VERSION "2.8"

NS_ :

BS_:

BU_: Advantics_Charge_Controller Generic_Power_Modules

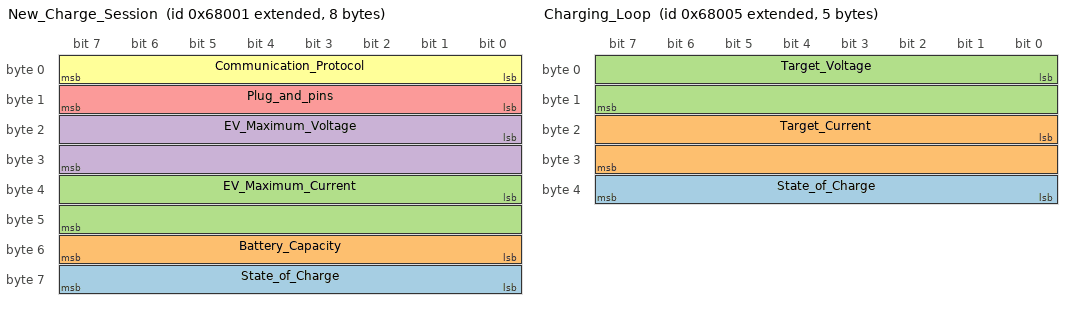
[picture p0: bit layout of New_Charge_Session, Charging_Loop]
BO_ 2147909633 New_Charge_Session: 8 Advantics_Charge_Controller
 SG_ State_of_Charge : 56|8@1+ (1,0) [0|100] "%" Vector__XXX
 SG_ Battery_Capacity : 48|8@1+ (2,0) [0|510] "kWh" Vector__XXX
 SG_ EV_Maximum_Current : 32|16@1+ (0.1,0) [0|0] "Amps" Vector__XXX
 SG_ EV_Maximum_Voltage : 16|16@1+ (0.1,0) [0|0] "Volts" Vector__XXX
 SG_ Plug_and_pins : 8|8@1+ (1,0) [0|0] "" Vector__XXX
 SG_ Communication_Protocol : 0|8@1+ (1,0) [0|0] "" Vector__XXX

BO_ 2147909634 Insulation_Test: 2 Advantics_Charge_Controller
 SG_ Test_Voltage : 0|16@1+ (0.1,0) [0|0] "Volts" Vector__XXX

BO_ 2147909635 Precharge: 4 Advantics_Charge_Controller
 SG_ Maximum_Current : 16|16@1+ (0.1,0) [0|0] "Amps" Vector__XXX
 SG_ Target_Voltage : 0|16@1+ (0.1,0) [0|0] "Volts" Vector__XXX

BO_ 2147909636 Charge_Status_Change: 1 Advantics_Charge_Controller
 SG_ Vehicle_Ready_for_Charging : 0|8@1+ (1,0) [0|0] "" Vector__XXX

BO_ 2147909637 Charging_Loop: 5 Advantics_Charge_Controller
 SG_ State_of_Charge : 32|8@1+ (1,0) [0|100] "%" Vector__XXX
 SG_ Target_Current : 16|16@1- (0.1,0) [0|0] "Amps" Vector__XXX
 SG_ Target_Voltage : 0|16@1+ (0.1,0) [0|0] "Volts" Vector__XXX

BO_ 2147909638 Emergency_Stop: 1 Advantics_Charge_Controller
 SG_ Origin : 0|8@1+ (1,0) [0|0] "" Vector__XXX

BO_ 2147909639 Charge_Session_Finished: 1 Advantics_Charge_Controller
 SG_ State : 0|8@1+ (1,0) [0|0] "" Vector__XXX

BO_ 2147909641 Advantics_Controller_Status: 1 Advantics_Charge_Controller
 SG_ State : 0|8@1+ (1,0) [0|0] "" Vector__XXX

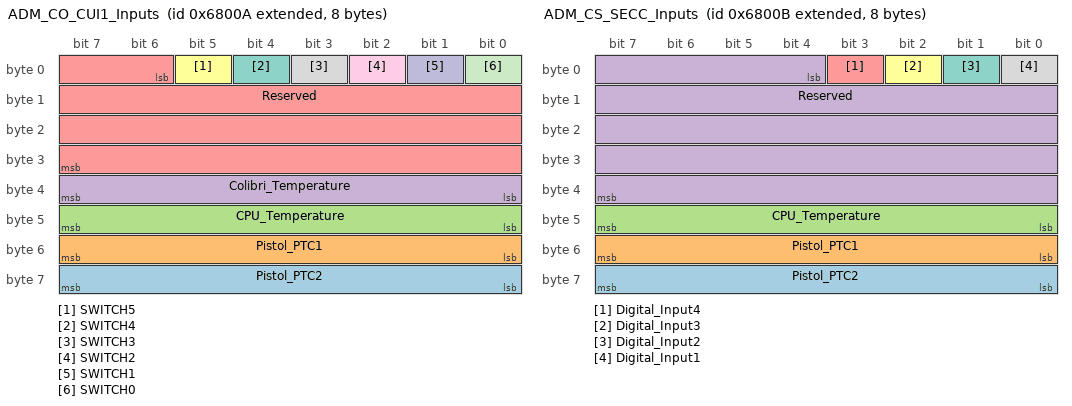
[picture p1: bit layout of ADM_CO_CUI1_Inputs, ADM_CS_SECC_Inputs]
BO_ 2147909642 ADM_CO_CUI1_Inputs: 8 Advantics_Charge_Controller
 SG_ Pistol_PTC2 : 56|8@1+ (1,-40) [-40|215] "°C" Vector__XXX
 SG_ Pistol_PTC1 : 48|8@1+ (1,-40) [-40|215] "°C" Vector__XXX
 SG_ CPU_Temperature : 40|8@1+ (1,-40) [-40|215] "°C" Vector__XXX
 SG_ Colibri_Temperature : 32|8@1+ (1,-40) [-40|215] "°C" Vector__XXX
 SG_ Reserved : 6|26@1+ (1,0) [0|0] "" Vector__XXX
 SG_ SWITCH5 : 5|1@1+ (1,0) [0|1] "" Vector__XXX
 SG_ SWITCH4 : 4|1@1+ (1,0) [0|1] "" Vector__XXX
 SG_ SWITCH3 : 3|1@1+ (1,0) [0|1] "" Vector__XXX
 SG_ SWITCH2 : 2|1@1+ (1,0) [0|1] "" Vector__XXX
 SG_ SWITCH1 : 1|1@1+ (1,0) [0|1] "" Vector__XXX
 SG_ SWITCH0 : 0|1@1+ (1,0) [0|1] "" Vector__XXX

BO_ 2147909643 ADM_CS_SECC_Inputs: 8 Advantics_Charge_Controller
 SG_ Pistol_PTC2 : 56|8@1+ (1,-40) [-40|215] "°C" Vector__XXX
 SG_ Pistol_PTC1 : 48|8@1+ (1,-40) [-40|215] "°C" Vector__XXX
 SG_ CPU_Temperature : 40|8@1+ (1,-40) [-40|215] "°C" Vector__XXX
 SG_ Reserved : 4|36@1+ (1,0) [0|0] "" Vector__XXX
 SG_ Digital_Input4 : 3|1@1+ (1,0) [0|1] "" Vector__XXX
 SG_ Digital_Input3 : 2|1@1+ (1,0) [0|1] "" Vector__XXX
 SG_ Digital_Input2 : 1|1@1+ (1,0) [0|1] "" Vector__XXX
 SG_ Digital_Input1 : 0|1@1+ (1,0) [0|1] "" Vector__XXX

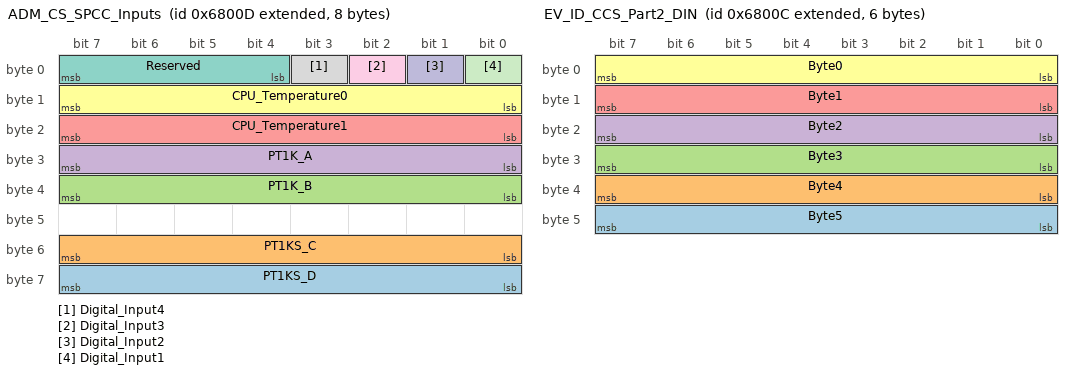
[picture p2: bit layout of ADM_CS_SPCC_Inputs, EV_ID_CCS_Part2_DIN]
BO_ 2147909645 ADM_CS_SPCC_Inputs: 8 Advantics_Charge_Controller
 SG_ PT1KS_D : 56|8@1+ (1,-40) [-40|215] "°C" Vector__XXX
 SG_ PT1KS_C : 48|8@1+ (1,-40) [-40|215] "°C" Vector__XXX
 SG_ PT1K_B : 32|8@1+ (1,-40) [-40|215] "°C" Vector__XXX
 SG_ PT1K_A : 24|8@1+ (1,-40) [-40|215] "°C" Vector__XXX
 SG_ CPU_Temperature1 : 16|8@1+ (1,-40) [-40|215] "°C" Vector__XXX
 SG_ CPU_Temperature0 : 8|8@1+ (1,-40) [-40|215] "°C" Vector__XXX
 SG_ Reserved : 4|4@1+ (1,0) [0|0] "" Vector__XXX
 SG_ Digital_Input4 : 3|1@1+ (1,0) [0|1] "" Vector__XXX
 SG_ Digital_Input3 : 2|1@1+ (1,0) [0|1] "" Vector__XXX
 SG_ Digital_Input2 : 1|1@1+ (1,0) [0|1] "" Vector__XXX
 SG_ Digital_Input1 : 0|1@1+ (1,0) [0|1] "" Vector__XXX

BO_ 2147909644 EV_ID_CCS_Part2_DIN: 6 Advantics_Charge_Controller
 SG_ Byte5 : 40|8@1+ (1,0) [0|0] "" Vector__XXX
 SG_ Byte4 : 32|8@1+ (1,0) [0|0] "" Vector__XXX
 SG_ Byte3 : 24|8@1+ (1,0) [0|0] "" Vector__XXX
 SG_ Byte2 : 16|8@1+ (1,0) [0|0] "" Vector__XXX
 SG_ Byte1 : 8|8@1+ (1,0) [0|0] "" Vector__XXX
 SG_ Byte0 : 0|8@1+ (1,0) [0|0] "" Vector__XXX

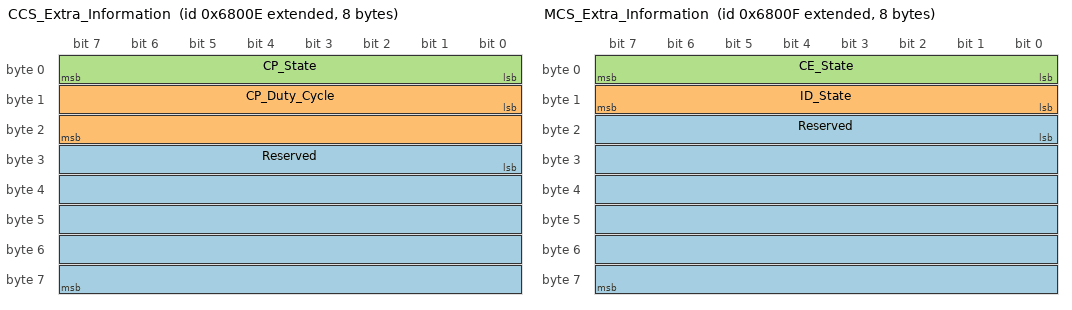
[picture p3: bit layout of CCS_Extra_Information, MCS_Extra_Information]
BO_ 2147909646 CCS_Extra_Information: 8 Advantics_Charge_Controller
 SG_ Reserved : 24|40@1+ (1,0) [0|0] "" Vector__XXX
 SG_ CP_Duty_Cycle : 8|16@1+ (0.1,0) [0|100] "%" Vector__XXX
 SG_ CP_State : 0|8@1+ (1,0) [0|0] "" Vector__XXX

BO_ 2147909647 MCS_Extra_Information: 8 Advantics_Charge_Controller
 SG_ Reserved : 16|48@1+ (1,0) [0|0] "" Vector__XXX
 SG_ ID_State : 8|8@1+ (1,0) [0|0] "" Vector__XXX
 SG_ CE_State : 0|8@1+ (1,0) [0|0] "" Vector__XXX

BO_ 2147909648 Charger_Diagnostic_Status: 8 Advantics_Charge_Controller
 SG_ Reserved_Flags : 35|29@1+ (1,0) [0|0] "" Vector__XXX
 SG_ PowerPermitWithdrawn : 34|1@1+ (1,0) [0|0] "" Vector__XXX
 SG_ SessionStoppedBeforeCharge : 33|1@1+ (1,0) [0|0] "" Vector__XXX
 SG_ EVChargingSystemIncompatibility : 32|1@1+ (1,0) [0|0] "" Vector__XXX
 SG_ EVChargingVoltageOutOfRange : 31|1@1+ (1,0) [0|0] "" Vector__XXX
 SG_ EVChargingCurrentDifferential : 30|1@1+ (1,0) [0|0] "" Vector__XXX
 SG_ EVRESSMalfunction : 29|1@1+ (1,0) [0|0] "" Vector__XXX
 SG_ EVConnectorLockFault : 28|1@1+ (1,0) [0|0] "" Vector__XXX
 SG_ EVShiftPosition : 27|1@1+ (1,0) [0|0] "" Vector__XXX
 SG_ EVRESSTemperatureInhibit : 26|1@1+ (1,0) [0|0] "" Vector__XXX
 SG_ CommunicationSetupTimeout : 25|1@1+ (1,0) [0|0] "" Vector__XXX
 SG_ V2GProtocolNotAllowed : 24|1@1+ (1,0) [0|0] "" Vector__XXX
 SG_ V2GParameterNotSupported : 23|1@1+ (1,0) [0|0] "" Vector__XXX
 SG_ V2GSessionIDUnexpected : 22|1@1+ (1,0) [0|0] "" Vector__XXX
 SG_ V2GSequenceError : 21|1@1+ (1,0) [0|0] "" Vector__XXX
 SG_ ChargeEnableStateUnexpected : 20|1@1+ (1,0) [0|0] "" Vector__XXX
 SG_ ChargeEnableFault : 19|1@1+ (1,0) [0|0] "" Vector__XXX
 SG_ ControlPilotStateUnexpected : 18|1@1+ (1,0) [0|0] "" Vector__XXX
 SG_ ControlPilotFault : 17|1@1+ (1,0) [0|0] "" Vector__XXX
 SG_ BidirectionalNotSupported : 16|1@1+ (1,0) [0|0] "" Vector__XXX
 SG_ RangeModeNotSupported : 15|1@1+ (1,0) [0|0] "" Vector__XXX
 SG_ CANBusError : 14|1@1+ (1,0) [0|0] "" Vector__XXX
 SG_ NodeDisconnected : 13|1@1+ (1,0) [0|0] "" Vector__XXX
 SG_ InternalError : 12|1@1+ (1,0) [0|0] "" Vector__XXX
 SG_ ChargerSequenceError : 11|1@1+ (1,0) [0|0] "" Vector__XXX
 SG_ HighTemperature : 10|1@1+ (1,0) [0|0] "" Vector__XXX
 SG_ PowerModuleRampDownTimeout : 9|1@1+ (1,0) [0|0] "" Vector__XXX
 SG_ PowerModuleDisabled : 8|1@1+ (1,0) [0|0] "" Vector__XXX
 SG_ PowerModuleCANTimeout : 7|1@1+ (1,0) [0|0] "" Vector__XXX
 SG_ PowerModuleFault : 6|1@1+ (1,0) [0|0] "" Vector__XXX
 SG_ InsulationMonitorFault : 5|1@1+ (1,0) [0|0] "" Vector__XXX
 SG_ InsulationFault : 4|1@1+ (1,0) [0|0] "" Vector__XXX
 SG_ ConnectorLockFailure : 3|1@1+ (1,0) [0|0] "" Vector__XXX
 SG_ OutputDriverFault : 2|1@1+ (1,0) [0|0] "" Vector__XXX
 SG_ EmergencyStopLoopOpen : 1|1@1+ (1,0) [0|0] "" Vector__XXX
 SG_ InterlockFault : 0|1@1+ (1,0) [0|0] "" Vector__XXX

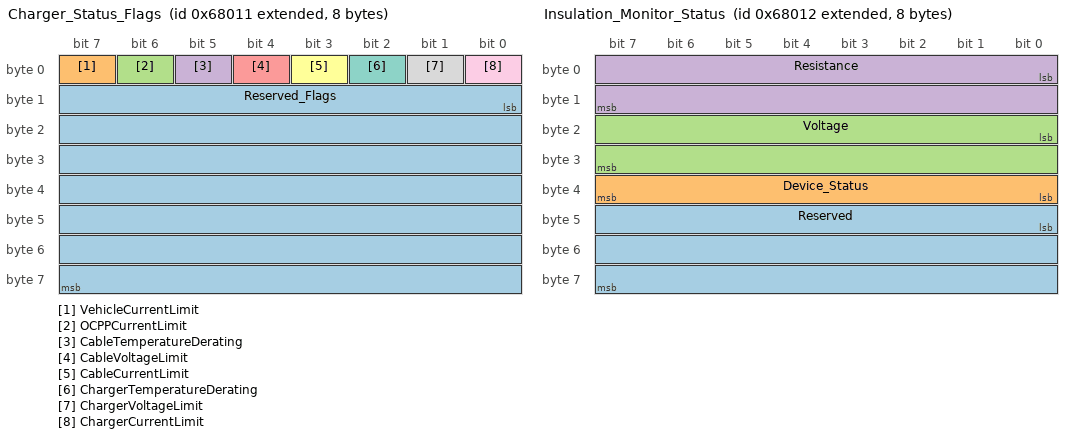
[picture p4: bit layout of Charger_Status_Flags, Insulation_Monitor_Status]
BO_ 2147909649 Charger_Status_Flags: 8 Advantics_Charge_Controller
 SG_ Reserved_Flags : 8|56@1+ (1,0) [0|0] "" Vector__XXX
 SG_ VehicleCurrentLimit : 7|1@1+ (1,0) [0|0] "" Vector__XXX
 SG_ OCPPCurrentLimit : 6|1@1+ (1,0) [0|0] "" Vector__XXX
 SG_ CableTemperatureDerating : 5|1@1+ (1,0) [0|0] "" Vector__XXX
 SG_ CableVoltageLimit : 4|1@1+ (1,0) [0|0] "" Vector__XXX
 SG_ CableCurrentLimit : 3|1@1+ (1,0) [0|0] "" Vector__XXX
 SG_ ChargerTemperatureDerating : 2|1@1+ (1,0) [0|0] "" Vector__XXX
 SG_ ChargerVoltageLimit : 1|1@1+ (1,0) [0|0] "" Vector__XXX
 SG_ ChargerCurrentLimit : 0|1@1+ (1,0) [0|0] "" Vector__XXX

BO_ 2147909650 Insulation_Monitor_Status: 8 Advantics_Charge_Controller
 SG_ Reserved : 40|24@1+ (1,0) [0|0] "" Vector__XXX
 SG_ Device_Status : 32|8@1+ (1,0) [0|0] "" Vector__XXX
 SG_ Voltage : 16|16@1+ (1,0) [0|0] "Volts" Vector__XXX
 SG_ Resistance : 0|16@1+ (1,0) [0|0] "kOhms" Vector__XXX

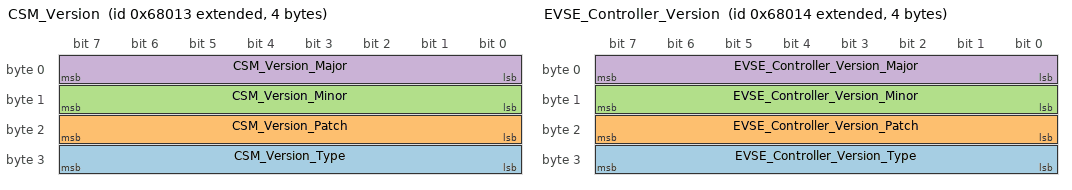
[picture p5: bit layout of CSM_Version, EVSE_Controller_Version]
BO_ 2147909651 CSM_Version: 4 Advantics_Charge_Controller
 SG_ CSM_Version_Type : 24|8@1+ (1,0) [0|0] "" Vector__XXX
 SG_ CSM_Version_Patch : 16|8@1+ (1,0) [0|0] "" Vector__XXX
 SG_ CSM_Version_Minor : 8|8@1+ (1,0) [0|0] "" Vector__XXX
 SG_ CSM_Version_Major : 0|8@1+ (1,0) [0|0] "" Vector__XXX

BO_ 2147909652 EVSE_Controller_Version: 4 Advantics_Charge_Controller
 SG_ EVSE_Controller_Version_Type : 24|8@1+ (1,0) [0|0] "" Vector__XXX
 SG_ EVSE_Controller_Version_Patch : 16|8@1+ (1,0) [0|0] "" Vector__XXX
 SG_ EVSE_Controller_Version_Minor : 8|8@1+ (1,0) [0|0] "" Vector__XXX
 SG_ EVSE_Controller_Version_Major : 0|8@1+ (1,0) [0|0] "" Vector__XXX

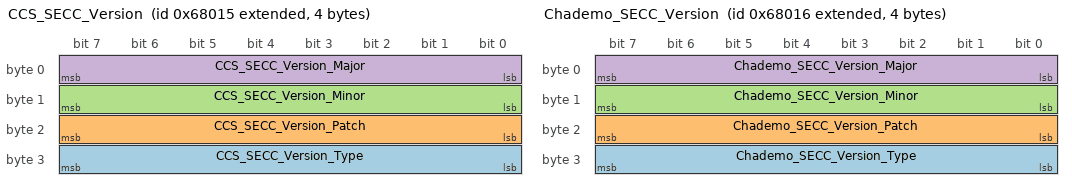
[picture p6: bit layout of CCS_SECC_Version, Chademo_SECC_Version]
BO_ 2147909653 CCS_SECC_Version: 4 Advantics_Charge_Controller
 SG_ CCS_SECC_Version_Type : 24|8@1+ (1,0) [0|0] "" Vector__XXX
 SG_ CCS_SECC_Version_Patch : 16|8@1+ (1,0) [0|0] "" Vector__XXX
 SG_ CCS_SECC_Version_Minor : 8|8@1+ (1,0) [0|0] "" Vector__XXX
 SG_ CCS_SECC_Version_Major : 0|8@1+ (1,0) [0|0] "" Vector__XXX

BO_ 2147909654 Chademo_SECC_Version: 4 Advantics_Charge_Controller
 SG_ Chademo_SECC_Version_Type : 24|8@1+ (1,0) [0|0] "" Vector__XXX
 SG_ Chademo_SECC_Version_Patch : 16|8@1+ (1,0) [0|0] "" Vector__XXX
 SG_ Chademo_SECC_Version_Minor : 8|8@1+ (1,0) [0|0] "" Vector__XXX
 SG_ Chademo_SECC_Version_Major : 0|8@1+ (1,0) [0|0] "" Vector__XXX

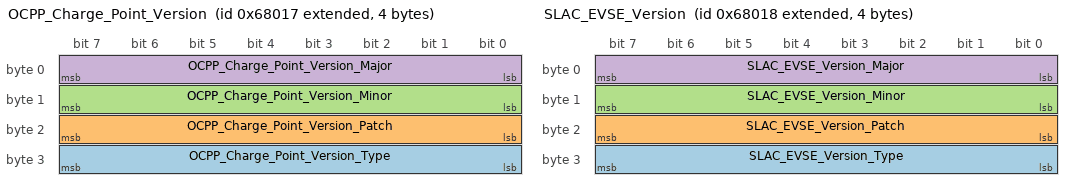
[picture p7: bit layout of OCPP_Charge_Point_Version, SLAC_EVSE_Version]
BO_ 2147909655 OCPP_Charge_Point_Version: 4 Advantics_Charge_Controller
 SG_ OCPP_Charge_Point_Version_Type : 24|8@1+ (1,0) [0|0] "" Vector__XXX
 SG_ OCPP_Charge_Point_Version_Patch : 16|8@1+ (1,0) [0|0] "" Vector__XXX
 SG_ OCPP_Charge_Point_Version_Minor : 8|8@1+ (1,0) [0|0] "" Vector__XXX
 SG_ OCPP_Charge_Point_Version_Major : 0|8@1+ (1,0) [0|0] "" Vector__XXX

BO_ 2147909656 SLAC_EVSE_Version: 4 Advantics_Charge_Controller
 SG_ SLAC_EVSE_Version_Type : 24|8@1+ (1,0) [0|0] "" Vector__XXX
 SG_ SLAC_EVSE_Version_Patch : 16|8@1+ (1,0) [0|0] "" Vector__XXX
 SG_ SLAC_EVSE_Version_Minor : 8|8@1+ (1,0) [0|0] "" Vector__XXX
 SG_ SLAC_EVSE_Version_Major : 0|8@1+ (1,0) [0|0] "" Vector__XXX

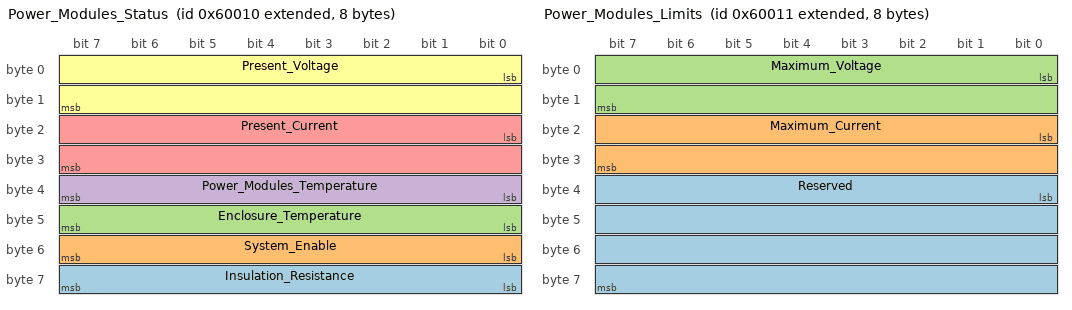
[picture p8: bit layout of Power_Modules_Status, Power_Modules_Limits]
BO_ 2147876880 Power_Modules_Status: 8 Generic_Power_Modules
 SG_ Insulation_Resistance : 56|8@1+ (2,0) [0|0] "kOhms" Vector__XXX
 SG_ System_Enable : 48|8@1+ (1,0) [0|0] "" Vector__XXX
 SG_ Enclosure_Temperature : 40|8@1+ (1,-40) [-40|215] "°C" Vector__XXX
 SG_ Power_Modules_Temperature : 32|8@1+ (1,-40) [-40|215] "°C" Vector__XXX
 SG_ Present_Current : 16|16@1- (0.1,0) [0|0] "Amps" Vector__XXX
 SG_ Present_Voltage : 0|16@1+ (0.1,0) [0|0] "Volts" Vector__XXX

BO_ 2147876881 Power_Modules_Limits: 8 Generic_Power_Modules
 SG_ Reserved : 32|32@1+ (1,0) [0|0] "" Vector__XXX
 SG_ Maximum_Current : 16|16@1- (0.1,0) [0|0] "Amps" Vector__XXX
 SG_ Maximum_Voltage : 0|16@1+ (0.1,0) [0|0] "Volts" Vector__XXX

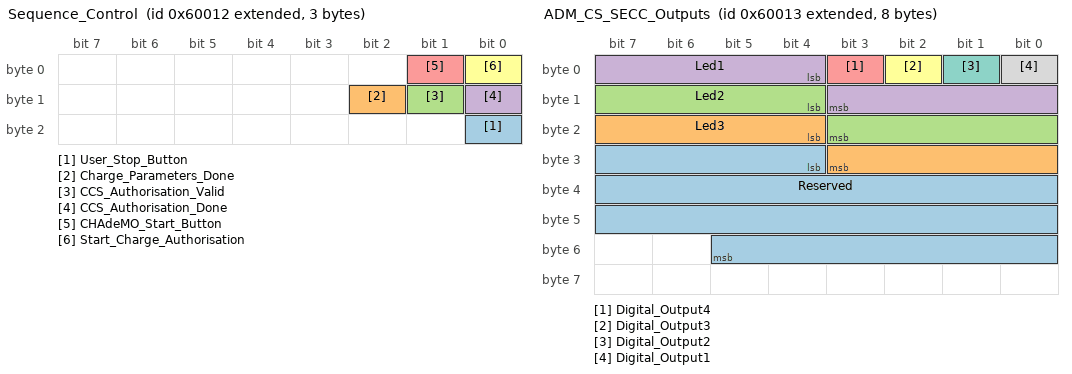
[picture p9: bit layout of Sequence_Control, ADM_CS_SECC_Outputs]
BO_ 2147876882 Sequence_Control: 3 Generic_Power_Modules
 SG_ User_Stop_Button : 16|1@1+ (1,0) [0|0] "" Vector__XXX
 SG_ Charge_Parameters_Done : 10|1@1+ (1,0) [0|0] "" Vector__XXX
 SG_ CCS_Authorisation_Valid : 9|1@1+ (1,0) [0|0] "" Vector__XXX
 SG_ CCS_Authorisation_Done : 8|1@1+ (1,0) [0|0] "" Vector__XXX
 SG_ CHAdeMO_Start_Button : 1|1@1+ (1,0) [0|0] "" Vector__XXX
 SG_ Start_Charge_Authorisation : 0|1@1+ (1,0) [0|0] "" Vector__XXX

BO_ 2147876883 ADM_CS_SECC_Outputs: 8 Generic_Power_Modules
 SG_ Reserved : 28|26@1+ (1,0) [0|0] "" Vector__XXX
 SG_ Led3 : 20|8@1+ (1,0) [0|255] "" Vector__XXX
 SG_ Led2 : 12|8@1+ (1,0) [0|255] "" Vector__XXX
 SG_ Led1 : 4|8@1+ (1,0) [0|255] "" Vector__XXX
 SG_ Digital_Output4 : 3|1@1+ (1,0) [0|1] "" Vector__XXX
 SG_ Digital_Output3 : 2|1@1+ (1,0) [0|1] "" Vector__XXX
 SG_ Digital_Output2 : 1|1@1+ (1,0) [0|1] "" Vector__XXX
 SG_ Digital_Output1 : 0|1@1+ (1,0) [0|1] "" Vector__XXX

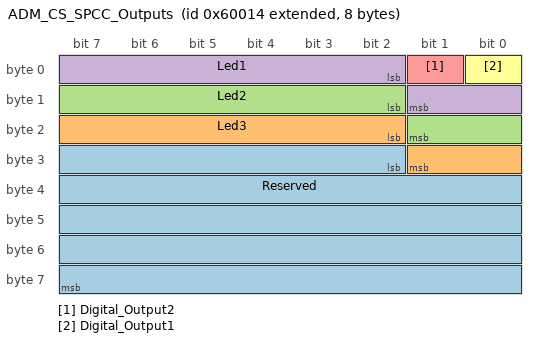
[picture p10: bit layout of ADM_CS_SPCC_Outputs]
BO_ 2147876884 ADM_CS_SPCC_Outputs: 8 Generic_Power_Modules
 SG_ Reserved : 26|38@1+ (1,0) [0|0] "" Vector__XXX
 SG_ Led3 : 18|8@1+ (1,0) [0|255] "" Vector__XXX
 SG_ Led2 : 10|8@1+ (1,0) [0|255] "" Vector__XXX
 SG_ Led1 : 2|8@1+ (1,0) [0|255] "" Vector__XXX
 SG_ Digital_Output2 : 1|1@1+ (1,0) [0|1] "" Vector__XXX
 SG_ Digital_Output1 : 0|1@1+ (1,0) [0|1] "" Vector__XXX

CM_ BO_ 2147909633 "
                Information about an incoming vehicle. Sent periodically from the moment a car is
                plugged in and all the information are known. Until power modules send a
                <<Power_Modules_Status.System_Enable>> with value  __Allowed__.
            ";
CM_ SG_ 2147909633 State_of_Charge "Battery SoC in percent.";
CM_ SG_ 2147909633 Battery_Capacity "Total battery capacity (optional, not all communication protocols give it).";
CM_ SG_ 2147909633 EV_Maximum_Current "Maximum battery current (optional, not all communication protocols give it).";
CM_ SG_ 2147909633 EV_Maximum_Voltage "Maximum battery voltage.";
CM_ SG_ 2147909633 Plug_and_pins "Plug type and DC pins selected by the car.";
CM_ SG_ 2147909633 Communication_Protocol "The charging protocol the car is using.";
CM_ BO_ 2147909634 "
                Test the insulation of the cable by applying a voltage from the charger. The battery
                is not connected yet. Power modules report <<Power_Modules_Status.Present_Voltage>>
                and <<Power_Modules_Status.Insulation_Resistance>> and the controller decides when
                the test passes or fails.

                Safety standards require a minimum of 100 Ohms/V insulation resistance. With a
                typical test voltage of 500 V, insulation resistance should be >= 50 kOhms.
            ";
CM_ SG_ 2147909634 Test_Voltage "
                    Voltage to apply.

                    Will be set back to 0 at the end of the test.
                ";
CM_ BO_ 2147909635 "
                Precharge procedure, with CCS only. The vehicle decides to consider precharge done
                when it senses voltage on its inlet to be close at 20 V to battery voltage.

                Charger is expected to match battery voltage at its output while having no load,
                apart from the capacitors on the line. When charging this capacitive load, it shall
                not output more current than <<Precharge.Maximum_Current>>.
            ";
CM_ SG_ 2147909635 Maximum_Current "
                    Maximum current allowed by the vehicle (shouldn't be more than 2A).

                    Will be set back to 0 at the end of the precharge procedure.
                ";
CM_ SG_ 2147909635 Target_Voltage "Voltage to apply.";
CM_ BO_ 2147909636 "
                Signal a change in the charging procedure. Sent once only when something change.
            ";
CM_ SG_ 2147909636 Vehicle_Ready_for_Charging "
                    Tells when the vehicle intend to start or stop the charge.

                    If value is __Charge_Started__, the power modules must be ready for the
                    charging loop at any moment (with CCS it can still be in several hours).

                    When value is __Charge_Stopped__, the vehicle stopped the charging process.
                ";
CM_ BO_ 2147909637 "
                Sent during the main charging loop. The vehicle is basically requesting current.
                Note that while the request is expressed in both voltage and current, it is up to
                power modules to determine which control mode they should run (ie. constant current,
                constant voltage or constant power).

                WARNING: The vehicle might not necessarily ramps up or down its requests.

                IMPORTANT: It is also sent at few other moments in the charging process with values
                <<Charging_Loop.Target_Voltage>> == 0 and <<Charging_Loop.Target_Current>> == 0.
                This has the meaning of telling the power modules to go into a sort of \"Standby\"
                mode. The power modules should turn off any power processing function, while remaning
                ready to receive future requests.
            ";
CM_ SG_ 2147909637 State_of_Charge "Battery SoC in percent (informative, do not rely on it).";
CM_ SG_ 2147909637 Target_Current "Current to provide.";
CM_ SG_ 2147909637 Target_Voltage "Voltage to apply.";
CM_ BO_ 2147909638 "
                Sent from the moment an emergency stop has been triggered.

                Emergency_Stop are not explicitly rearmable. You either power cycle the whole setup.
                Or the emergency condition disappear, and the message will stop being sent once the
                controller pass in a state where it reevaluates emergency conditions.
            ";
CM_ SG_ 2147909638 Origin "From which side the emergency stop came from.";
CM_ BO_ 2147909639 "Charging is over and the vehicle should unplug soon.";
CM_ SG_ 2147909639 State "Was the session terminated cleanly or not.";
CM_ BO_ 2147909641 "
                Periodic message reporting the current status of the controller. This message is
                sent all the time as soon as the application on the controller is running.

                IMPORTANT: Power modules should implement a timeout on the reception of this message.
                If the controller does not send this message within 200 ms, then power modules
                should consider the controller to be in a defective state and stop any power function
                as soon as possible.
            ";
CM_ SG_ 2147909641 State "
                    Current internal state. For information only.

                    Initialising:: Controller's applications are starting up.
                    Waiting_For_PEV:: Controller is idle and ready for a plug-in.
                    Negotiating_Connection:: Controller is plugged to a car and the connection is
                        being initialised. Important charge information are exchanged.
                    Connected_With_Full_Info:: All charge information from the PEV were retrieved
                        and a charge session can be considered to be properly open.
                    Insulation_Test:: Insulation of the charge cable is being tested.
                    Precharge:: Charger is matching its output voltage to the present voltage of the
                        battery.
                    Waiting_For_Charge:: PEV is about to begin the actual charging.
                    Charging:: Main charging loop going on.
                    Ending_Charge:: A normal charge stop condition happenned and the PEV is exiting
                        the charging loop.
                    Welding_Detection:: PEV is testing if its contactors are welded.
                    Closing_Communication:: PEV can unplug and charger is reinitialising in order to
                        then go back to __Waiting_For_PEV__.
                    CCS_Authorisation_Process:: Special state in CCS to authorise user.
                    Not_Available:: Controller has been made unavailable by
                        __Sequence_Control.Start_Charge_Authorisation__
                ";
CM_ BO_ 2147909642 "
                Controller (ADM-CO-CUI1 hardware variant, ie. \"generic/mobile\") is reporting various
                information about its inputs. It is sent every seconds (for temperature channels).
                Or on change for other digital inputs.
            ";
CM_ SG_ 2147909642 Pistol_PTC2 "Measured temperature sensor on second PTC channel associated to this pistol.";
CM_ SG_ 2147909642 Pistol_PTC1 "Measured temperature sensor on first PTC channel associated to this pistol.";
CM_ SG_ 2147909642 CPU_Temperature "Temperature reported by the CPU chip of the charge controller.";
CM_ SG_ 2147909642 Colibri_Temperature "Temperature measured on the Colibri SoM board of the charge controller.";
CM_ SG_ 2147909642 Reserved "Reserved bits for future uses.";
CM_ SG_ 2147909642 SWITCH5 "
                    Reports the logical state of SWITCH5 (J7, position 6).
                    Needs to be declared as monitored in `/srv/config.cfg`:

                        [hardware]
                        switch5 = Monitor
                ";
CM_ SG_ 2147909642 SWITCH4 "
                    Reports the logical state of SWITCH4 (J7, position 5).
                    Needs to be declared as monitored in `/srv/config.cfg`:

                        [hardware]
                        switch4 = Monitor
                ";
CM_ SG_ 2147909642 SWITCH3 "
                    Reports the logical state of SWITCH3 (J7, position 4).
                    Needs to be declared as monitored in `/srv/config.cfg`:

                        [hardware]
                        switch3 = Monitor
                ";
CM_ SG_ 2147909642 SWITCH2 "
                    Reports the logical state of SWITCH2 (J7, position 3).
                    Needs to be declared as monitored in `/srv/config.cfg`:

                        [hardware]
                        switch2 = Monitor
                ";
CM_ SG_ 2147909642 SWITCH1 "
                    Reports the logical state of SWITCH1 (J7, position 2).
                    Needs to be declared as monitored in `/srv/config.cfg`:

                        [hardware]
                        switch1 = Monitor
                ";
CM_ SG_ 2147909642 SWITCH0 "
                    Reports the logical state of SWITCH0 (J7, position 1).
                    Needs to be declared as monitored in `/srv/config.cfg`:

                        [hardware]
                        switch0 = Monitor
                ";
CM_ BO_ 2147909643 "
                Controller (ADM-CS-SECC hardware variant, ie. \"DIN rail\") is reporting various
                information about its inputs. It is sent every seconds (for temperature channels).
                Or on change for other digital inputs.
            ";
CM_ SG_ 2147909643 Pistol_PTC2 "Measured temperature sensor on second PTC channel associated to this pistol.";
CM_ SG_ 2147909643 Pistol_PTC1 "Measured temperature sensor on first PTC channel associated to this pistol.";
CM_ SG_ 2147909643 CPU_Temperature "Temperature reported by the CPU chip of the charge controller.";
CM_ SG_ 2147909643 Reserved "Reserved bits for future uses.";
CM_ SG_ 2147909643 Digital_Input4 "
                    Reports the logical state of DIG_IN4 (CONN6, position 4).
                    Needs to be declared as monitored in `/srv/config.cfg`:

                        [hardware]
                        dig_in4 = Monitor
                ";
CM_ SG_ 2147909643 Digital_Input3 "
                    Reports the logical state of DIG_IN3 (CONN6, position 3).
                    Needs to be declared as monitored in `/srv/config.cfg`:

                        [hardware]
                        dig_in3 = Monitor
                ";
CM_ SG_ 2147909643 Digital_Input2 "
                    Reports the logical state of DIG_IN2 (CONN6, position 2).
                    Needs to be declared as monitored in `/srv/config.cfg`:

                        [hardware]
                        dig_in2 = Monitor
                ";
CM_ SG_ 2147909643 Digital_Input1 "
                    Reports the logical state of DIG_IN1 (CONN6, position 1).
                    Needs to be declared as monitored in `/srv/config.cfg`:

                        [hardware]
                        dig_in1 = Monitor
                ";
CM_ BO_ 2147909645 "
                Controller (ADM-CS-SPCC hardware variant) is reporting various
                information about its inputs. It is sent every seconds (for temperature channels).
                Or on change for other digital inputs.
            ";
CM_ SG_ 2147909645 PT1KS_D "Measured temperature sensor on PT1KS_D input.";
CM_ SG_ 2147909645 PT1KS_C "Measured temperature sensor on PT1KS_C input.";
CM_ SG_ 2147909645 PT1K_B "Measured temperature sensor on PT1K_B input.";
CM_ SG_ 2147909645 PT1K_A "
                This input is used as CHAdeMO pistol solenoid input when the controller is configured for CHAdeMO.
                When the controller is configured for MCS, CCS DC or AC, this input can be used as a temperature sensor.
                ";
CM_ SG_ 2147909645 CPU_Temperature1 "Temperature reported by the CPU chip of the charge controller.";
CM_ SG_ 2147909645 CPU_Temperature0 "Temperature reported by the CPU chip of the charge controller.";
CM_ SG_ 2147909645 Reserved "Reserved bits for future uses.";
CM_ SG_ 2147909645 Digital_Input4 "
                    Reports the logical state of DIG_IN4 (CONN6, position 4).
                    Needs to be declared as monitored in `/srv/config.cfg`:

                        [hardware]
                        dig_in4 = Monitor
                ";
CM_ SG_ 2147909645 Digital_Input3 "
                    Reports the logical state of DIG_IN3 (CONN6, position 3).
                    Needs to be declared as monitored in `/srv/config.cfg`:

                        [hardware]
                        dig_in3 = Monitor
                ";
CM_ SG_ 2147909645 Digital_Input2 "
                    Reports the logical state of DIG_IN2 (CONN6, position 2).
                    Needs to be declared as monitored in `/srv/config.cfg`:

                        [hardware]
                        dig_in2 = Monitor
                ";
CM_ SG_ 2147909645 Digital_Input1 "
                    Reports the logical state of DIG_IN1 (CONN6, position 1).
                    Needs to be declared as monitored in `/srv/config.cfg`:

                        [hardware]
                        dig_in1 = Monitor
                ";
CM_ BO_ 2147909644 "
                The EV ID provided by the vehicle in CCS DIN SPEC 70121 and ISO 15118-2.
                EV ID for CCS ISO 15118-20 is not supported by this message.
                (the EV ID is defined as a string of max 255 characters in ISO 15118-20)
            ";
CM_ SG_ 2147909644 Byte5 "
                    Byte 5 of the EV ID.
                ";
CM_ SG_ 2147909644 Byte4 "
                    Byte 4 of the EV ID.
                ";
CM_ SG_ 2147909644 Byte3 "
                    Byte 3 of the EV ID.
                ";
CM_ SG_ 2147909644 Byte2 "
                    Byte 2 of the EV ID.
                ";
CM_ SG_ 2147909644 Byte1 "
                    Byte 1 of the EV ID.
                ";
CM_ SG_ 2147909644 Byte0 "
                    Byte 0 of the EV ID.
                ";
CM_ BO_ 2147909646 "
            Extra information from CCS (for information only).  
            !!! info
                    Available since version 4.2
            ";
CM_ SG_ 2147909646 Reserved "Reserved bits for future uses.";
CM_ SG_ 2147909646 CP_Duty_Cycle "Measured PWM duty cycle on the CP line.";
CM_ SG_ 2147909646 CP_State "Measured CP state.";
CM_ BO_ 2147909647 "
            Extra information from MCS (for information only).  
            !!! info
                    Available since version 4.2
            ";
CM_ SG_ 2147909647 Reserved "Reserved bits for future uses.";
CM_ SG_ 2147909647 ID_State "Measured ID state.";
CM_ SG_ 2147909647 CE_State "Measured CE state.";
CM_ BO_ 2147909648 "
                Error codes currently raised by the charge controller. One bit per code, several
                can be set at once. Codes are named after DIN DKE SPEC 99003 wherever the
                specification defines one.

                Sent every second, and immediately whenever a code is raised or cleared, so
                the codes currently raised can be read at any time rather than only at the moment
                they change.

                How long a code stays raised is one of two behaviours, chosen per pistol in
                the controller's config file:

                - **Kept until the next session**, the default. A code outlives the session
                  that raised it: it stays raised through the return to idle and is cleared
                  only when the next plug-in starts a new session. 
                  whenever __Advantics_Controller_Status.State__ reads __Waiting_For_PEV__,
                  a code set here belongs to the session that has just finished. It tells you
                  why that session ended, not that something is wrong with the charger right now.
                - **Cleared on the way back to idle**, with the config entry 
                  `clear_error_codes_on_idle = true` in the pistol section.
                  A code is dropped as soon as the controller cycles
                  back to __Waiting_For_PEV__, so it is never visible outside the session
                  that raised it.

                Live status, such as which limit the charge is currently held to, is in
                <<Charger_Status_Flags>> instead, so a listener of these codes is never woken up
                by a status change.

                The pilot-line and V2G codes only apply to CCS and MCS sessions, and the __EV*__
                ones report what the vehicle declared about itself in DC_EVStatus.EVErrorCode
                (DIN SPEC 70121 and DIN EN ISO 15118-2 only).
            ";
CM_ SG_ 2147909648 Reserved_Flags "Reserved bits for future uses.";
CM_ SG_ 2147909648 PowerPermitWithdrawn "The vehicle stopped granting its hardware power permit while power transfer was
                    in progress. Not reported when the permit drops at the normal end of
                    a charge.";
CM_ SG_ 2147909648 SessionStoppedBeforeCharge "The session ended before the charge phase started: the vehicle was connected and
                    communicating, but the charger never delivered power. Says that a
                    session was lost early, not why -- any code raised alongside it is
                    the reason. On its own it means the vehicle or the operator ended
                    it, or the negotiation never completed.";
CM_ SG_ 2147909648 EVChargingSystemIncompatibility "Vehicle reports DC_EVStatus.EVErrorCode = FAILED_ChargingSystemIncompatibility.";
CM_ SG_ 2147909648 EVChargingVoltageOutOfRange "Vehicle reports DC_EVStatus.EVErrorCode = FAILED_ChargingVoltageOutOfRange.";
CM_ SG_ 2147909648 EVChargingCurrentDifferential "Vehicle reports DC_EVStatus.EVErrorCode = FAILED_ChargingCurrentdifferential.";
CM_ SG_ 2147909648 EVRESSMalfunction "Vehicle reports DC_EVStatus.EVErrorCode = FAILED_EVRESSMalfunction.";
CM_ SG_ 2147909648 EVConnectorLockFault "Vehicle reports DC_EVStatus.EVErrorCode = FAILED_ChargerConnectorLockFault.";
CM_ SG_ 2147909648 EVShiftPosition "Vehicle reports DC_EVStatus.EVErrorCode = FAILED_EVShiftPosition.";
CM_ SG_ 2147909648 EVRESSTemperatureInhibit "Vehicle reports DC_EVStatus.EVErrorCode = FAILED_RESSTemperatureInhibit.";
CM_ SG_ 2147909648 CommunicationSetupTimeout "The vehicle did not complete the session setup within the time allowed by
                    `communication_setup_timeout`, counted from the communication link coming up.";
CM_ SG_ 2147909648 V2GProtocolNotAllowed "The negotiated application protocol is disabled, or not allowed over this connection.";
CM_ SG_ 2147909648 V2GParameterNotSupported "The application protocol the vehicle asked for is not supported.
                    DIN DKE SPEC 99003 use case 8.4.";
CM_ SG_ 2147909648 V2GSessionIDUnexpected "The vehicle used a session ID we do not know.";
CM_ SG_ 2147909648 V2GSequenceError "The vehicle sent a request that is not allowed in the current sequence state.";
CM_ SG_ 2147909648 ChargeEnableStateUnexpected "Charge Enable is in a valid state, but not one the charging sequence allows at that
                    point, such as leaving C while power is being transferred or dropping
                    to A with a session still running. Readings the sequence treats as
                    noise are not reported.";
CM_ SG_ 2147909648 ChargeEnableFault "The MCS Charge Enable line is in error state E. The line itself is at fault.";
CM_ SG_ 2147909648 ControlPilotStateUnexpected "Control Pilot is in a valid state, but not one the charging sequence allows at that
                    point: B where C or D is required, C or D where only B is, or a drop
                    to A with a session still running. The normal unplug once a session
                    has ended is not reported.";
CM_ SG_ 2147909648 ControlPilotFault "The CCS Control Pilot line is in an error state: E (0 V) or F, the charger
                    signalling itself unavailable. The line itself is at fault.";
CM_ SG_ 2147909648 BidirectionalNotSupported "The vehicle requested discharge from a charger that is not bidirectional.";
CM_ SG_ 2147909648 RangeModeNotSupported "Range mode setpoints were requested from a charger configured without range mode.";
CM_ SG_ 2147909648 CANBusError "Sending on the power modules CAN bus failed.";
CM_ SG_ 2147909648 NodeDisconnected "A required controller application stopped answering its heartbeat.";
CM_ SG_ 2147909648 InternalError "An unhandled error occurred inside the controller.";
CM_ SG_ 2147909648 ChargerSequenceError "The power modules refused a state transition the controller asked for.";
CM_ SG_ 2147909648 HighTemperature "A monitored temperature crossed its charge-stop threshold.";
CM_ SG_ 2147909648 PowerModuleRampDownTimeout "The power modules did not bring the output current down in time when the charge
                    ended. The contactors were left closed.";
CM_ SG_ 2147909648 PowerModuleDisabled "The power modules withdrew Power_Modules_Status.System_Enable during a powered phase.";
CM_ SG_ 2147909648 PowerModuleCANTimeout "No Power_Modules_Status received within the configured timeout.";
CM_ SG_ 2147909648 PowerModuleFault "The power modules are in a fault or defective state.";
CM_ SG_ 2147909648 InsulationMonitorFault "The insulation monitoring device reports an internal device error. Distinct from
                    InsulationFault, which is the measured resistance being too low.";
CM_ SG_ 2147909648 InsulationFault "Insulation resistance is below the allowed limit.";
CM_ SG_ 2147909648 ConnectorLockFailure "The connector lock driver reports a fault. AC charging only.";
CM_ SG_ 2147909648 OutputDriverFault "The industrial digital output driver reports a fault.";
CM_ SG_ 2147909648 EmergencyStopLoopOpen "The emergency stop current loop is open.";
CM_ SG_ 2147909648 InterlockFault "The interlock protection input is pulled low. Any safety device wired to that
                    line can pull it down to stop the charge. Causes that have their own code
                    are excluded here: the emergency stop loop, the industrial output driver,
                    and the controller pulling the line low itself.";
CM_ BO_ 2147909649 "
                Live status flags of the charge controller. One bit per flag, several can be set
                at once. During a charge session, a flag can be set then goes back to 0 on its own
                once its condition is gone.

                Sent every second, and immediately whenever a flag changes.

                - When two limits give the same value, both flags are set.
                - The same flags cover charging and discharging, and in range mode they cover
                  both ends of the range at once.
                - A power limit becomes a current limit once divided by the present voltage, so
                  which limit is the lowest can change as the voltage moves. Several frames may
                  follow in quick succession when it does.
            ";
CM_ SG_ 2147909649 Reserved_Flags "Reserved bits for future uses.";
CM_ SG_ 2147909649 VehicleCurrentLimit "The maximum current the vehicle declared is what holds the current down, below every
                    limit of our own. DC only.";
CM_ SG_ 2147909649 OCPPCurrentLimit "The limit set by OCPP smart charging is what holds the current down, either as a
                    current or as a power divided by the present voltage. Applies to charging, not
                    discharging.";
CM_ SG_ 2147909649 CableTemperatureDerating "A monitored temperature is derating the cable's current limit. Set whenever that
                    derating applies, whether or not it is what holds the current down.";
CM_ SG_ 2147909649 CableVoltageLimit "The cable's own rated voltage (`max_cable_voltage`) is what holds the target voltage
                    below what the vehicle asked for. DC only.";
CM_ SG_ 2147909649 CableCurrentLimit "The cable's own rating is what holds the current down: `max_cable_current`, or
                    `max_cable_power` divided by the present voltage. On AC,
                    `max_cable_phase_current`.";
CM_ SG_ 2147909649 ChargerTemperatureDerating "A monitored temperature is derating the charger's current limit. Set whenever that
                    derating applies, whether or not it is what holds the current down: it is a real
                    reduction of what the charger can do.";
CM_ SG_ 2147909649 ChargerVoltageLimit "The charger's own rated voltage (`max_charger_voltage`, or a lower limit the power
                    modules report) is what holds the target voltage below what the vehicle asked
                    for. DC only.";
CM_ SG_ 2147909649 ChargerCurrentLimit "The charger's own rating is what holds the current down: `max_charger_current`,
                    `max_charger_power` divided by the present voltage, their discharge
                    counterparts, or a lower limit the power modules report. On AC,
                    `max_charger_phase_current`.";
CM_ BO_ 2147909650 "
                What the insulation monitor the charge controller reads itself is measuring.

                Sent every second, and only when the controller is configured to read a supported
                insulation monitor. A charger that measures the insulation itself, and reports it
                in <<Power_Modules_Status.Insulation_Resistance>>, never sees this message: the
                value is already its own.

                This is a reading, not a verdict. The outcome of the insulation test is the charge
                sequence moving on, and a failure is reported as __InsulationFault__ or
                __InsulationMonitorFault__ in <<Charger_Diagnostic_Status>>.
            ";
CM_ SG_ 2147909650 Reserved "Reserved bits for future uses.";
CM_ SG_ 2147909650 Device_Status "
                    What the device says about itself and about the resistance it measures,
                    ordered from no news to worst news.

                    The first two are the controller's own answers rather than the device's,
                    and are the two that mean there is no measurement:

                    - __Not_Available__: no insulation monitor is being read at all. It cannot
                      appear on this message, which is only sent when one is.
                    - __No_Communication__: a monitor is configured and is not answering --
                      not yet, or not any more. A silent device is not a faulty one, so this is
                      not reported as __Device_Error__.

                    __Prewarning__, __Warning__ and __Alarm__ are the device telling you about
                    the resistance, and the measurement stands. __Device_Error__ is the device
                    reporting a fault of its own, and then there is no measurement: on a device
                    error this ISOMETER re-purposes its measurement channels to report earth
                    and system connection instead of resistance and voltage.
                ";
CM_ SG_ 2147909650 Voltage "
                    Voltage measured by the device on the line it watches. This is its own
                    measurement, independent of the charger's, so it can be compared against
                    <<Power_Modules_Status.Present_Voltage>>.

                    65535 means there is no measurement to report.
                ";
CM_ SG_ 2147909650 Resistance "
                    Insulation resistance measured by the device.

                    65535 means there is no measurement to report, which is also what
                    __Device_Status__ then says. It is never reported as 0, which would read as a
                    dead short.
                ";
CM_ BO_ 2147909651 "
                Reports the software version of the CSM (Charge Station Management) application.

                Sent periodically once the application is running. Versions rarely change (a new
                version requires restarting the application), so a slow polling interval on the
                receiving side is fine.
            ";
CM_ SG_ 2147909651 CSM_Version_Type "Release type of the CSM application version.";
CM_ SG_ 2147909651 CSM_Version_Patch "Patch version number of the CSM application.";
CM_ SG_ 2147909651 CSM_Version_Minor "Minor version number of the CSM application.";
CM_ SG_ 2147909651 CSM_Version_Major "Major version number of the CSM application.";
CM_ BO_ 2147909652 "
                Reports the software version of the EVSE controller application itself.

                Sent periodically once the application is running. Versions rarely change (a new
                version requires restarting the application), so a slow polling interval on the
                receiving side is fine.
            ";
CM_ SG_ 2147909652 EVSE_Controller_Version_Type "Release type of the EVSE controller application version.";
CM_ SG_ 2147909652 EVSE_Controller_Version_Patch "Patch version number of the EVSE controller application.";
CM_ SG_ 2147909652 EVSE_Controller_Version_Minor "Minor version number of the EVSE controller application.";
CM_ SG_ 2147909652 EVSE_Controller_Version_Major "Major version number of the EVSE controller application.";
CM_ BO_ 2147909653 "
                Reports the software version of the CCS SECC (Supply Equipment Communication
                Controller) application.

                Sent periodically once the application is running. Only relevant on installations
                that have CCS enabled; otherwise reported as 0.0.0.
            ";
CM_ SG_ 2147909653 CCS_SECC_Version_Type "Release type of the CCS SECC application version.";
CM_ SG_ 2147909653 CCS_SECC_Version_Patch "Patch version number of the CCS SECC application.";
CM_ SG_ 2147909653 CCS_SECC_Version_Minor "Minor version number of the CCS SECC application.";
CM_ SG_ 2147909653 CCS_SECC_Version_Major "Major version number of the CCS SECC application.";
CM_ BO_ 2147909654 "
                Reports the software version of the CHAdeMO SECC (Supply Equipment Communication
                Controller) application.

                Sent periodically once the application is running. Only relevant on installations
                that have CHAdeMO enabled; otherwise reported as 0.0.0.
            ";
CM_ SG_ 2147909654 Chademo_SECC_Version_Type "Release type of the CHAdeMO SECC application version.";
CM_ SG_ 2147909654 Chademo_SECC_Version_Patch "Patch version number of the CHAdeMO SECC application.";
CM_ SG_ 2147909654 Chademo_SECC_Version_Minor "Minor version number of the CHAdeMO SECC application.";
CM_ SG_ 2147909654 Chademo_SECC_Version_Major "Major version number of the CHAdeMO SECC application.";
CM_ BO_ 2147909655 "
                Reports the software version of the OCPP charge point application.

                Sent periodically once the application is running. Versions rarely change (a new
                version requires restarting the application), so a slow polling interval on the
                receiving side is fine.
            ";
CM_ SG_ 2147909655 OCPP_Charge_Point_Version_Type "Release type of the OCPP charge point application version.";
CM_ SG_ 2147909655 OCPP_Charge_Point_Version_Patch "Patch version number of the OCPP charge point application.";
CM_ SG_ 2147909655 OCPP_Charge_Point_Version_Minor "Minor version number of the OCPP charge point application.";
CM_ SG_ 2147909655 OCPP_Charge_Point_Version_Major "Major version number of the OCPP charge point application.";
CM_ BO_ 2147909656 "
                Reports the software version of the SLAC (Signal Level Attenuation
                Characterization) EVSE application.

                Sent periodically once the application is running. Versions rarely change (a new
                version requires restarting the application), so a slow polling interval on the
                receiving side is fine.
            ";
CM_ SG_ 2147909656 SLAC_EVSE_Version_Type "Release type of the SLAC EVSE application version.";
CM_ SG_ 2147909656 SLAC_EVSE_Version_Patch "Patch version number of the SLAC EVSE application.";
CM_ SG_ 2147909656 SLAC_EVSE_Version_Minor "Minor version number of the SLAC EVSE application.";
CM_ SG_ 2147909656 SLAC_EVSE_Version_Major "Major version number of the SLAC EVSE application.";
CM_ BO_ 2147876880 "
                Periodic message reporting the current status of power modules. This message should
                be sent all the time when power modules are running.

                [IMPORTANT]
                ====
                Controller implements a timeout on the reception of this message. It is used as a
                source of interlock condition. As such, this interlock source is evaluated only in
                states where power modules should be alive.

                Therefore, it is NOT evaluated when waiting for a PEV to plug-in, or when
                negotiating the connection with the PEV.

                Power modules should be alive from the moment <<New_Charge_Session>> is sent, until
                <<Charge_Session_Finished>> is sent. At any other time, power modules are allowed to
                sleep and not send this message.
                ====
            ";
CM_ SG_ 2147876880 Insulation_Resistance "
                    Reports the current insulation resistance, in multiple of 2 kOhms.

                    TIP: If the RCD sensor only gives a boolean value, then 255 correspond to a __Valid__
                    insulation, and 0 to an __Invalid__ insulation.

                    IMPORTANT: Whenever a power function is used after the insulation test, if this
                    signal reports an insulation resistance below the limit of 100 Ohms/V, then this
                    is considered as an interlock condition and an emergency stop is carried out.
                ";
CM_ SG_ 2147876880 System_Enable "
                        Tells if charging is allowed.

                        When <<New_Charge_Session>> is sent, the controller waits for this signal
                        to be 1 to continue the charge sequence.

                        If 0 is emitted between <<New_Charge_Session>> and before the charging loop
                        starts, the charge controller tells the vehicle the charging service is
                        unavailable.

                        If 0 is emitted during the charging loop, this is interpreted as an
                        emergency shutdown requested by power modules.
                ";
CM_ SG_ 2147876880 Enclosure_Temperature "Top temperature sensed in the enclosure.";
CM_ SG_ 2147876880 Power_Modules_Temperature "Top temperature sensed in power modules.";
CM_ SG_ 2147876880 Present_Current "Current measurement at the output of the charger";
CM_ SG_ 2147876880 Present_Voltage "Voltage measurement at the output of the charger";
CM_ BO_ 2147876881 "
                Periodic message reporting the current limits of power modules. This message can be
                sent as often as needed (but not faster than 100ms).

                Values reported here will be capped by limits statically defined in the config file.
                If a value is set to 0, then it means to use default limits from the config file.
            ";
CM_ SG_ 2147876881 Reserved "Reserved bytes for future uses.";
CM_ SG_ 2147876881 Maximum_Current "Maximum output current of the charger";
CM_ SG_ 2147876881 Maximum_Voltage "Max output voltage of the charger";
CM_ BO_ 2147876882 "
                This message has most flags controlling the charge sequence (apart from System_Enable).

                The first byte is for flags having effect before a charge session starts.
                The second byte is for flags having effect during parameters negotiation.
                The third byte is for flags having effect during power stages (insulation test,
                precharge and charging).

                The controller config file should have the entry \"use_sequence_flags = true\" in the
                \"[charger]\" section in order to take them into account.

                To make sure the controller is taking a first message as initialisation of these
                flags, send this first message after Advantics_Controller_Status message reports a
                State of Waiting_For_PEV (value 1).

                All signals default to value 0. Bits that are not used in this version should remain
                at 0 to avoid incompatibility with future versions.
            ";
CM_ SG_ 2147876882 User_Stop_Button "Simulate a press on the user stop button (for normal charge termination). Only acts on change (so you need to cycle it back to 0).";
CM_ SG_ 2147876882 Charge_Parameters_Done "Tells when fields in Power_Modules_Limits message can be considered stable and sent to the vehicle.";
CM_ SG_ 2147876882 CCS_Authorisation_Valid "Tells if authorisation of vehicle is valid (CCS only). Only meaningful when CCS_Authorisation_Done is 1.";
CM_ SG_ 2147876882 CCS_Authorisation_Done "Tells if authorisation of vehicle is finished (CCS only)";
CM_ SG_ 2147876882 CHAdeMO_Start_Button "Simulate a press on the CHAdeMO start button. Only acts on change (so you need to cycle it back to 0).";
CM_ SG_ 2147876882 Start_Charge_Authorisation "
                    Indicate if the controller should even attempt to start a charge session.
                    Suitable for external authorisation permit that happens before user is allowed
                    to plug or start a charge.

                    Set to 0 to disallow charging, and 1 to allow.

                    In CCS, it will keep CP PWM to 100%, even when detecting State B (9V).
                    In CHAdeMO, it will simply ignore the start button.
                    But in both case, it will register the user intent as wanting to charge. As soon
                    as this flag allows charging, it will then start the charge session.
                ";
CM_ BO_ 2147876883 "
                Controller (ADM-CS-SECC hardware variant, ie. \"DIN rail\") has various outputs that
                can be controlled through this message.
            ";
CM_ SG_ 2147876883 Reserved "Reserved bits for future uses.";
CM_ SG_ 2147876883 Led3 "
                    Sets the brightness of LED3 (CON 7) in a scale from 1 to 100.
                    Greater values than 100 will be treated as max brigthness.

                        [hardware]
                        led3 = CAN_Controlled
                ";
CM_ SG_ 2147876883 Led2 "
                    Sets the brightness of LED2 (CON 6) in a scale from 1 to 100.
                    Greater values than 100 will be treated as max brigthness.

                        [hardware]
                        led2 = CAN_Controlled
                ";
CM_ SG_ 2147876883 Led1 "
                    Sets the brightness of LED1 (CON5 5) in a scale from 1 to 100. 
                    Greater values than 100 will be treated as max brigthness.

                        [hardware]
                        led1 = CAN_Controlled
                ";
CM_ SG_ 2147876883 Digital_Output4 "
                    Reports the logical state of DIG_OUT4 (CONN5, position 4).
                    Needs to be declared as CAN Controlled in `/srv/config.cfg`:

                        [hardware]
                        dig_out4 = CAN_Controlled
                ";
CM_ SG_ 2147876883 Digital_Output3 "
                    Reports the logical state of DIG_OUT3 (CONN5, position 3).
                    Needs to be declared as CAN Controlled in `/srv/config.cfg`:

                        [hardware]
                        dig_out3 = CAN_Controlled
                ";
CM_ SG_ 2147876883 Digital_Output2 "
                    Reports the logical state of DIG_OUT2 (CONN5, position 2).
                    Needs to be declared as CAN Controlled in `/srv/config.cfg`:

                        [hardware]
                        dig_out2 = CAN_Controlled
                ";
CM_ SG_ 2147876883 Digital_Output1 "
                    Sets the logical state of DIG_OUT1 (CONN5, position 1).
                    Needs to be declared as CAN Controlled in `/srv/config.cfg`:

                        [hardware]
                        dig_out1 = CAN_Controlled
                ";
CM_ BO_ 2147876884 "
                Controller (ADM-CS-SPCC hardware variant) has various outputs that
                can be controlled through this message.
            ";
CM_ SG_ 2147876884 Reserved "Reserved bits for future uses.";
CM_ SG_ 2147876884 Led3 "
                    Sets the brightness of LED3 (CON105 13) in a scale from 1 to 100.
                    Greater values than 100 will be treated as max brigthness.

                        [hardware]
                        led3 = CAN_Controlled
                ";
CM_ SG_ 2147876884 Led2 "
                    Sets the brightness of LED2 (CON105 12) in a scale from 1 to 100.
                    Greater values than 100 will be treated as max brigthness.

                        [hardware]
                        led2 = CAN_Controlled
                ";
CM_ SG_ 2147876884 Led1 "
                    Sets the brightness of LED1 (CON105 11) in a scale from 1 to 100. 
                    Greater values than 100 will be treated as max brigthness.

                        [hardware]
                        led1 = CAN_Controlled
                ";
CM_ SG_ 2147876884 Digital_Output2 "
                    Reports the logical state of DIG_OUT2 (CONN5, position 2).
                    Needs to be declared as CAN Controlled in the config file:

                        [hardware]
                        dig_out2 = CAN_Controlled
                ";
CM_ SG_ 2147876884 Digital_Output1 "
                    Sets the logical state of DIG_OUT1 (CONN5, position 1).
                    Needs to be declared as CAN Controlled in the config file:

                        [hardware]
                        dig_out1 = CAN_Controlled
                ";
BA_DEF_ BO_  "GenMsgCycleTime" INT 0 65535;
BA_DEF_  "Baudrate" INT 0 10485760;
BA_DEF_DEF_  "GenMsgCycleTime" 0;
BA_DEF_DEF_  "Baudrate" 125000;
BA_ "Baudrate" 500000;
BA_ "GenMsgCycleTime" BO_ 2147909633 100;
BA_ "GenMsgCycleTime" BO_ 2147909634 100;
BA_ "GenMsgCycleTime" BO_ 2147909635 100;
BA_ "GenMsgCycleTime" BO_ 2147909637 100;
BA_ "GenMsgCycleTime" BO_ 2147909638 100;
BA_ "GenMsgCycleTime" BO_ 2147909641 100;
BA_ "GenMsgCycleTime" BO_ 2147909642 1000;
BA_ "GenMsgCycleTime" BO_ 2147909643 1000;
BA_ "GenMsgCycleTime" BO_ 2147909645 1000;
BA_ "GenMsgCycleTime" BO_ 2147909644 1000;
BA_ "GenMsgCycleTime" BO_ 2147909646 100;
BA_ "GenMsgCycleTime" BO_ 2147909647 100;
BA_ "GenMsgCycleTime" BO_ 2147909648 1000;
BA_ "GenMsgCycleTime" BO_ 2147909649 1000;
BA_ "GenMsgCycleTime" BO_ 2147909650 1000;
BA_ "GenMsgCycleTime" BO_ 2147909651 1000;
BA_ "GenMsgCycleTime" BO_ 2147909652 1000;
BA_ "GenMsgCycleTime" BO_ 2147909653 1000;
BA_ "GenMsgCycleTime" BO_ 2147909654 1000;
BA_ "GenMsgCycleTime" BO_ 2147909655 1000;
BA_ "GenMsgCycleTime" BO_ 2147909656 1000;
BA_ "GenMsgCycleTime" BO_ 2147876880 100;
BA_ "GenMsgCycleTime" BO_ 2147876883 1000;
BA_ "GenMsgCycleTime" BO_ 2147876884 1000;
VAL_ 2147909633 Plug_and_pins 0 "CCS_DC_Core" 1 "CCS_DC_Extended" 2 "CHAdeMO" 3 "CCS_AC" 4 "MCS" ;
VAL_ 2147909633 Communication_Protocol 0 "CCS_DIN_70121_2012_v2" 1 "CCS_ISO_15118_2010_v1" 2 "CCS_ISO_15118_2013_v2" 3 "CHAdeMO_v0.9" 4 "CHAdeMO_v1.0-v1.1-v1.2" 5 "CHAdeMO_v2.0" 6 "CCS_PWM" 7 "CCS_ISO_15118_2022" ;
VAL_ 2147909636 Vehicle_Ready_for_Charging 0 "Charge_Stopped" 1 "Charge_Started" ;
VAL_ 2147909638 Origin 1 "EVSE" 3 "PEV" ;
VAL_ 2147909639 State 0 "Clean_Stop" 1 "Rushed_Stop" ;
VAL_ 2147909641 State 0 "Initialising" 1 "Waiting_For_PEV" 2 "Negotiating_Connection" 3 "Connected_With_Full_Info" 4 "Insulation_Test" 5 "Precharge" 6 "Waiting_For_Charge" 7 "Charging" 8 "Ending_Charge" 9 "Welding_Detection" 10 "Closing_Communication" 11 "CCS_Authorisation_Process" 12 "Not_Available" 13 "Charge_Pause" ;
VAL_ 2147909646 CP_State 0 "E_or_F" 3 "D" 6 "C" 9 "B" 12 "A" ;
VAL_ 2147909647 ID_State 0 "Unmated" 1 "Mated" 2 "Mated_EVAux" 3 "Mated_EVSEAux" ;
VAL_ 2147909647 CE_State 0 "Undefined" 1 "A" 2 "B0" 3 "B0_Aux" 4 "B" 5 "B_Aux" 6 "C" 7 "C_Aux" 8 "EC" 9 "E" ;
VAL_ 2147909650 Device_Status 0 "Not_Available" 1 "No_Communication" 2 "OK" 3 "Prewarning" 4 "Warning" 5 "Alarm" 6 "Device_Error" ;
VAL_ 2147909651 CSM_Version_Type 0 "None" 1 "dev" 2 "rc" 3 "post" ;
VAL_ 2147909652 EVSE_Controller_Version_Type 0 "None" 1 "dev" 2 "rc" 3 "post" ;
VAL_ 2147909653 CCS_SECC_Version_Type 0 "None" 1 "dev" 2 "rc" 3 "post" ;
VAL_ 2147909654 Chademo_SECC_Version_Type 0 "None" 1 "dev" 2 "rc" 3 "post" ;
VAL_ 2147909655 OCPP_Charge_Point_Version_Type 0 "None" 1 "dev" 2 "rc" 3 "post" ;
VAL_ 2147909656 SLAC_EVSE_Version_Type 0 "None" 1 "dev" 2 "rc" 3 "post" ;
VAL_ 2147876880 System_Enable 0 "Not_Allowed" 1 "Allowed" ;
VAL_ 2147876882 User_Stop_Button 0 "Not_Pressed" 1 "Pressed" ;
VAL_ 2147876882 Charge_Parameters_Done 0 "Not_Done" 1 "Done" ;
VAL_ 2147876882 CCS_Authorisation_Valid 0 "Invalid" 1 "Valid" ;
VAL_ 2147876882 CCS_Authorisation_Done 0 "Not_Done" 1 "Done" ;
VAL_ 2147876882 CHAdeMO_Start_Button 0 "Not_Pressed" 1 "Pressed" ;
VAL_ 2147876882 Start_Charge_Authorisation 0 "Not_Allowed" 1 "Allowed" ;
